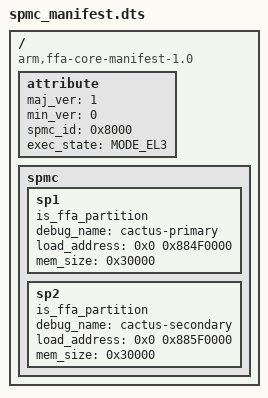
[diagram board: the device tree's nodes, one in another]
/*
 * Copyright (c) 2021, NVIDIA Corporation. All rights reserved.
 *
 * SPDX-License-Identifier: BSD-3-Clause
 */
/dts-v1/;

#define	AFF	00

#include <dt-bindings/memory/memory.h>

#undef POST
#define	POST \
	};

#define MODE_EL0	(0x0)
#define MODE_EL1	(0x1)
#define MODE_EL2	(0x2)
#define MODE_EL3	(0x3)

/ {
	compatible = "arm,ffa-core-manifest-1.0";
	#address-cells = <2>;
	#size-cells = <1>;

	attribute {
		maj_ver = <1>;
		min_ver = <0>;
		spmc_id = <0x8000>;
		exec_state = <MODE_EL3>;
	};

	spmc {
		sp1 {
			is_ffa_partition;
			debug_name = "cactus-primary";
			load_address = <0x0 0x884F0000>;
			mem_size = <0x30000>;
		};
		sp2 {
			is_ffa_partition;
			debug_name = "cactus-secondary";
			load_address = <0x0 0x885F0000>;
			mem_size = <0x30000>;
		};
	};
};
